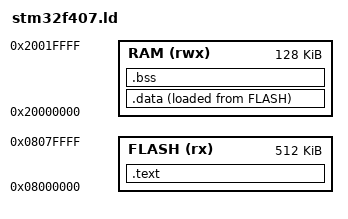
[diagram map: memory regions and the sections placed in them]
ENTRY(_start)

MEMORY
{
    FLASH (rx)  : ORIGIN = 0x08000000, LENGTH = 512K
    RAM   (rwx) : ORIGIN = 0x20000000, LENGTH = 128K
}

SECTIONS
{
    .text :
    {
        KEEP(*(.isr_vector))
        *(.text*)
        *(.rodata*)
        _etext = .;
    } > FLASH

    .data :
    {
        _sdata = .;
        *(.data*)
        _edata = .;
    } > RAM AT > FLASH

    .bss :
    {
        _sbss = .;
        *(.bss*)
        *(COMMON)
        _ebss = .;
    } > RAM

    /* Heap (for newlib _sbrk) */
    . = ALIGN(4);
    _end = .;
    end = .;

    /DISCARD/ :
    {
        *(.ARM.attributes)
        *(.comment)
    }
}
